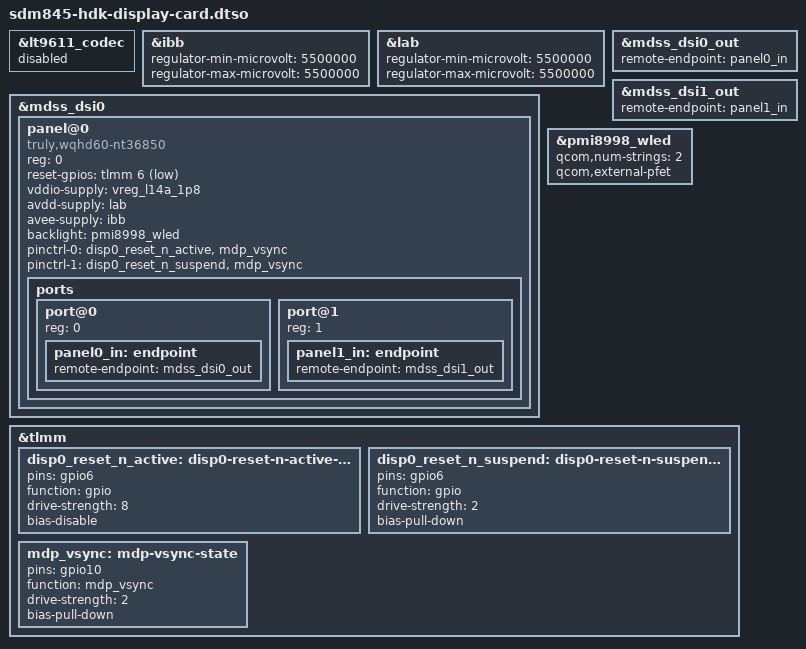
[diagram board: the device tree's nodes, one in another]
// SPDX-License-Identifier: BSD-3-Clause
/*
 * Copyright (c) Qualcomm Technologies, Inc. and/or its subsidiaries.
 */

/*
 * Display Card kit overlay.
 */

#include <dt-bindings/gpio/gpio.h>

/dts-v1/;
/plugin/;

/* Disable HDMI bridge related nodes (mutually exclusive with the display card) */
&lt9611_codec {
	status = "disabled";
};

&ibb {
	regulator-min-microvolt = <5500000>;
	regulator-max-microvolt = <5500000>;
};

&lab {
	regulator-min-microvolt = <5500000>;
	regulator-max-microvolt = <5500000>;
};

&mdss_dsi0 {
	#address-cells = <1>;
	#size-cells = <0>;

	panel@0 {
		compatible = "truly,wqhd60-nt36850";
		reg = <0>;

		reset-gpios = <&tlmm 6 GPIO_ACTIVE_LOW>;

		vddio-supply = <&vreg_l14a_1p8>;
		avdd-supply = <&lab>;
		avee-supply = <&ibb>;

		backlight = <&pmi8998_wled>;

		pinctrl-0 = <&disp0_reset_n_active>, <&mdp_vsync>;
		pinctrl-1 = <&disp0_reset_n_suspend>, <&mdp_vsync>;
		pinctrl-names = "default", "sleep";

		ports {
			#address-cells = <1>;
			#size-cells = <0>;

			port@0 {
				reg = <0>;

				panel0_in: endpoint {
					remote-endpoint = <&mdss_dsi0_out>;
				};
			};

			port@1 {
				reg = <1>;

				panel1_in: endpoint {
					remote-endpoint = <&mdss_dsi1_out>;
				};
			};
		};
	};
};

&mdss_dsi0_out {
	remote-endpoint = <&panel0_in>;
};

&mdss_dsi1_out {
	remote-endpoint = <&panel1_in>;
};

&pmi8998_wled {
	qcom,num-strings = <2>;
	qcom,external-pfet;

	status = "okay";
};

&tlmm {
	disp0_reset_n_active: disp0-reset-n-active-state {
		pins = "gpio6";
		function = "gpio";
		drive-strength = <8>;
		bias-disable;
	};

	disp0_reset_n_suspend: disp0-reset-n-suspend-state {
		pins = "gpio6";
		function = "gpio";
		drive-strength = <2>;
		bias-pull-down;
	};

	mdp_vsync: mdp-vsync-state {
		pins = "gpio10";
		function = "mdp_vsync";
		drive-strength = <2>;
		bias-pull-down;
	};
};
